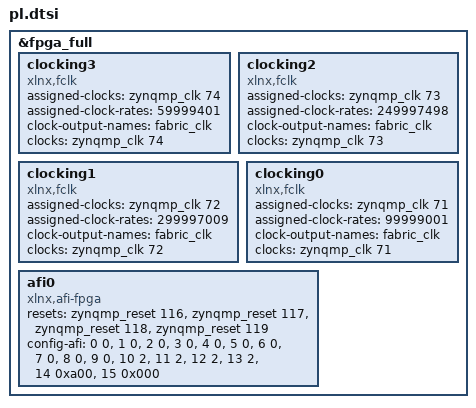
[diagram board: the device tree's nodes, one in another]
/dts-v1/;
/plugin/;
/ {
	fragment@0 {
		target = <&fpga_full>;
		overlay0: __overlay__ {
			//firmware-name = "kr260-base-firmware.bin";
			clocking3: clocking3 {
				compatible = "xlnx,fclk";
				assigned-clocks = <&zynqmp_clk 74>;
				assigned-clock-rates = <59999401>;
				#clock-cells = <0>;
				clock-output-names = "fabric_clk";
				clocks = <&zynqmp_clk 74>;
			};
			clocking2: clocking2 {
				compatible = "xlnx,fclk";
				assigned-clocks = <&zynqmp_clk 73>;
				assigned-clock-rates = <249997498>;
				#clock-cells = <0>;
				clock-output-names = "fabric_clk";
				clocks = <&zynqmp_clk 73>;
			};
			clocking1: clocking1 {
				compatible = "xlnx,fclk";
				assigned-clocks = <&zynqmp_clk 72>;
				assigned-clock-rates = <299997009>;
				#clock-cells = <0>;
				clock-output-names = "fabric_clk";
				clocks = <&zynqmp_clk 72>;
			};
			clocking0: clocking0 {
				compatible = "xlnx,fclk";
				assigned-clocks = <&zynqmp_clk 71>;
				assigned-clock-rates = <99999001>;
				#clock-cells = <0>;
				clock-output-names = "fabric_clk";
				clocks = <&zynqmp_clk 71>;
			};
			afi0: afi0 {
				compatible = "xlnx,afi-fpga";
				resets = <&zynqmp_reset 116>, <&zynqmp_reset 117>, <&zynqmp_reset 118>, <&zynqmp_reset 119>;
				config-afi = < 0 0>, <1 0>, <2 0>, <3 0>, <4 0>, <5 0>, <6 0>, <7 0>, <8 0>, <9 0>, <10 2>, <11 2>, <12 2>, <13 2>, <14 0xa00>, <15 0x000>;
			};
		};
	};
};
